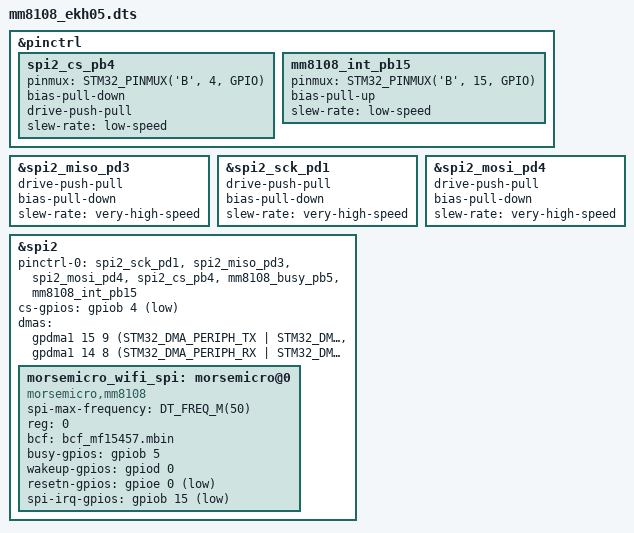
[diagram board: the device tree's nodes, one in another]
/*
 * Copyright 2025-2026 Morse Micro
 *
 * SPDX-License-Identifier: Apache-2.0
 */

/dts-v1/;
#include "mm8108_ekh05_common.dtsi"
#include <zephyr/dt-bindings/dma/stm32_dma.h>

/* MM Module SPI connecters */

&pinctrl {
	spi2_cs_pb4: spi2_cs_pb4 {
		pinmux = <STM32_PINMUX('B', 4, GPIO)>;
		bias-pull-down;
		drive-push-pull;
		slew-rate = "low-speed";
	};

	mm8108_int_pb15: mm8108_int_pb15 {
		pinmux = <STM32_PINMUX('B', 15, GPIO)>;
		bias-pull-up;
		slew-rate = "low-speed";
	};
};

&spi2_miso_pd3 {
	drive-push-pull;
	bias-pull-down;
	slew-rate = "very-high-speed";
};

&spi2_sck_pd1 {
	drive-push-pull;
	bias-pull-down;
	slew-rate = "very-high-speed";
};

&spi2_mosi_pd4 {
	drive-push-pull;
	bias-pull-down;
	slew-rate = "very-high-speed";
};

&spi2 {
	status = "okay";
	pinctrl-0 = <&spi2_sck_pd1 &spi2_miso_pd3 &spi2_mosi_pd4 &spi2_cs_pb4 &mm8108_busy_pb5 &mm8108_int_pb15>;
	pinctrl-names = "default";
	cs-gpios = <&gpiob 4 GPIO_ACTIVE_LOW>;

	//         channel slot channel-config (st,stm32-dma_v2.yaml)
	dmas = <&gpdma1 15 9 (STM32_DMA_PERIPH_TX | STM32_DMA_PRIORITY_VERY_HIGH)>,
		   <&gpdma1 14 8 (STM32_DMA_PERIPH_RX | STM32_DMA_PRIORITY_VERY_HIGH)>;
	dma-names = "tx", "rx";

	morsemicro_wifi_spi: morsemicro@0 {
		status = "okay";
		compatible = "morsemicro,mm8108";
		spi-max-frequency = <DT_FREQ_M(50)>;
		reg = <0>;

		bcf = "bcf_mf15457.mbin";
		busy-gpios = <&gpiob 5 GPIO_ACTIVE_HIGH>;
		wakeup-gpios = <&gpiod 0 GPIO_ACTIVE_HIGH>;
		resetn-gpios = <&gpioe 0 GPIO_ACTIVE_LOW>;
		spi-irq-gpios = <&gpiob 15 GPIO_ACTIVE_LOW>;
	};
};
